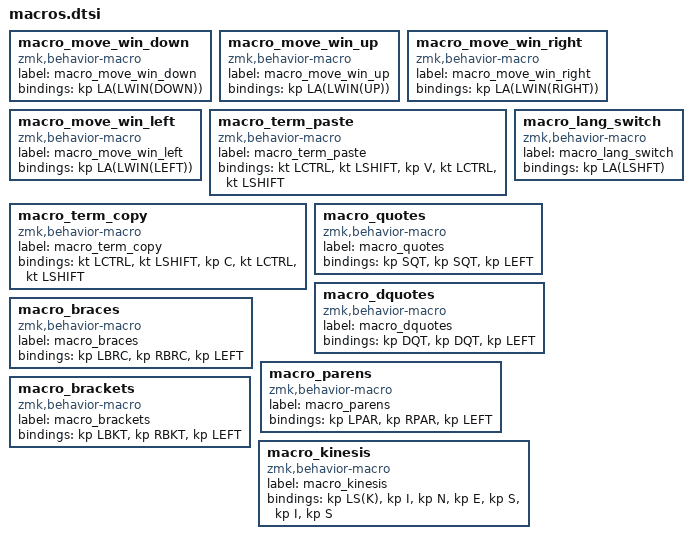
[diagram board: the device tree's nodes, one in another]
macro_move_win_down: macro_move_win_down{
compatible = "zmk,behavior-macro";
label = "macro_move_win_down";
#binding-cells = <0>;
bindings = <&kp LA(LWIN(DOWN))>;
};
macro_move_win_up: macro_move_win_up{
compatible = "zmk,behavior-macro";
label = "macro_move_win_up";
#binding-cells = <0>;
bindings = <&kp LA(LWIN(UP))>;
};
macro_move_win_right: macro_move_win_right{
compatible = "zmk,behavior-macro";
label = "macro_move_win_right";
#binding-cells = <0>;
bindings = <&kp LA(LWIN(RIGHT))>;
};
macro_move_win_left: macro_move_win_left{
compatible = "zmk,behavior-macro";
label = "macro_move_win_left";
#binding-cells = <0>;
bindings = <&kp LA(LWIN(LEFT))>;
};
macro_term_paste: macro_term_paste{
compatible = "zmk,behavior-macro";
label = "macro_term_paste";
#binding-cells = <0>;
bindings = <&kt LCTRL>, <&kt LSHIFT>, <&kp V>, <&kt LCTRL>, <&kt LSHIFT>;
};
macro_term_copy: macro_term_copy{
compatible = "zmk,behavior-macro";
label = "macro_term_copy";
#binding-cells = <0>;
bindings = <&kt LCTRL>, <&kt LSHIFT>, <&kp C>, <&kt LCTRL>, <&kt LSHIFT>;
};
macro_lang_switch: macro_lang_switch{
compatible = "zmk,behavior-macro";
label = "macro_lang_switch";
#binding-cells = <0>;
bindings = <&kp LA(LSHFT)>;
};
macro_quotes: macro_quotes{
compatible = "zmk,behavior-macro";
label = "macro_quotes";
#binding-cells = <0>;
bindings = <&kp SQT>, <&kp SQT>, <&kp LEFT>;
};
macro_dquotes: macro_dquotes{
compatible = "zmk,behavior-macro";
label = "macro_dquotes";
#binding-cells = <0>;
bindings = <&kp DQT>, <&kp DQT>, <&kp LEFT>;
};
macro_braces: macro_braces{
compatible = "zmk,behavior-macro";
label = "macro_braces";
#binding-cells = <0>;
bindings = <&kp LBRC>, <&kp RBRC>, <&kp LEFT>;
};
macro_parens: macro_parens{
compatible = "zmk,behavior-macro";
label = "macro_parens";
#binding-cells = <0>;
bindings = <&kp LPAR>, <&kp RPAR>, <&kp LEFT>;
};
macro_brackets: macro_brackets{
compatible = "zmk,behavior-macro";
label = "macro_brackets";
#binding-cells = <0>;
bindings = <&kp LBKT>, <&kp RBKT>, <&kp LEFT>;
};
macro_kinesis: macro_kinesis{
compatible = "zmk,behavior-macro";
label = "macro_kinesis";
#binding-cells = <0>;
bindings = <&kp LS(K)>, <&kp I>, <&kp N>, <&kp E>, <&kp S>, <&kp I>, <&kp S>;
};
